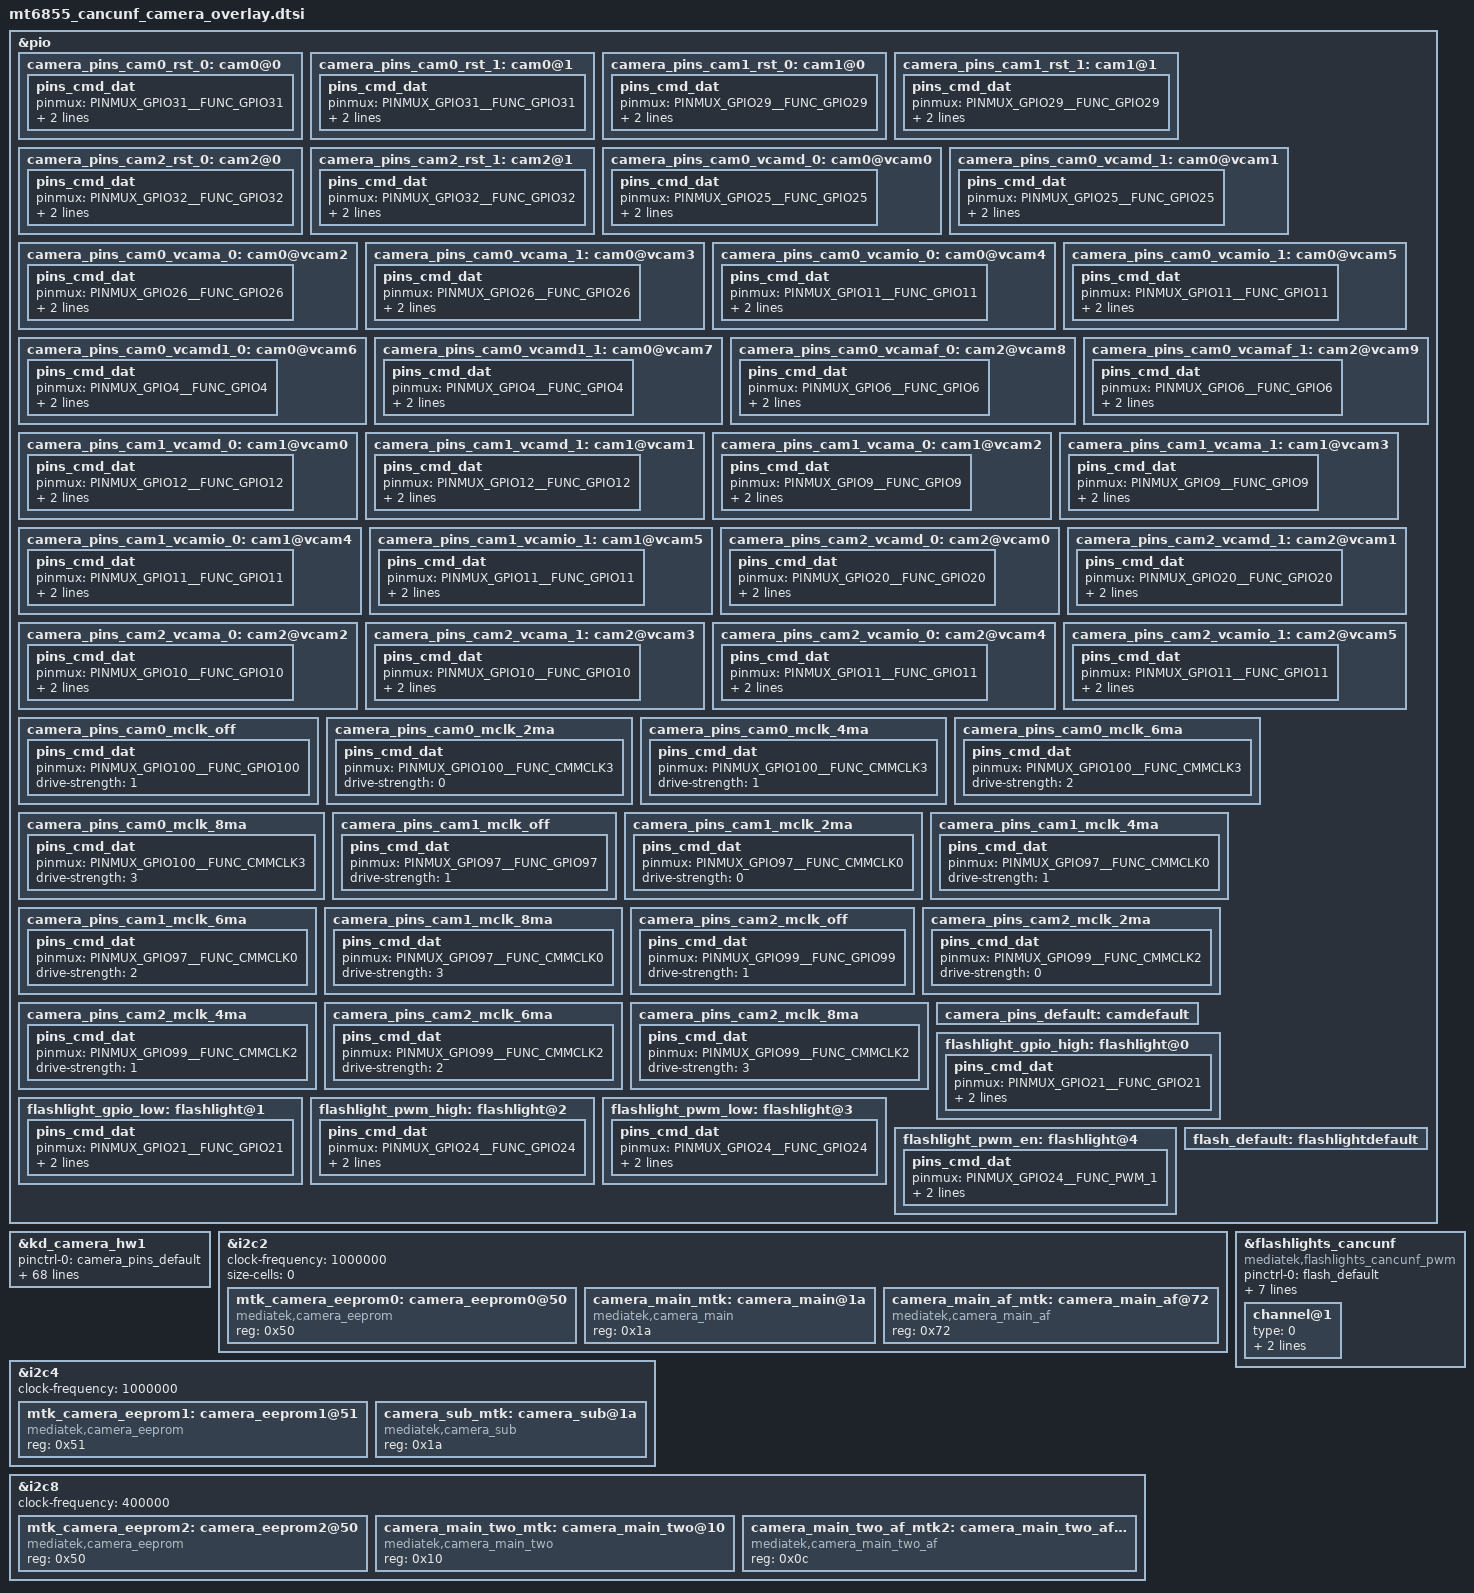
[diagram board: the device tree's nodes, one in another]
// SPDX-License-Identifier: GPL-2.0
/* Copyright (c) 2020 MediaTek Inc. */
/* CAMERA GPIO standardization */
&pio {
	camera_pins_cam0_rst_0: cam0@0 {
		pins_cmd_dat {
			pinmux = <PINMUX_GPIO31__FUNC_GPIO31>;
			slew-rate = <1>;
			output-low;
		};
	};
	camera_pins_cam0_rst_1: cam0@1 {
		pins_cmd_dat {
			pinmux = <PINMUX_GPIO31__FUNC_GPIO31>;
			slew-rate = <1>;
			output-high;
		};
	};
	camera_pins_cam1_rst_0: cam1@0 {
		pins_cmd_dat {
			pinmux = <PINMUX_GPIO29__FUNC_GPIO29>;
			slew-rate = <1>;
			output-low;
		};
	};
	camera_pins_cam1_rst_1: cam1@1 {
		pins_cmd_dat {
			pinmux = <PINMUX_GPIO29__FUNC_GPIO29>;
			slew-rate = <1>;
			output-high;
		};
	};
	camera_pins_cam2_rst_0: cam2@0 {
		pins_cmd_dat {
			pinmux = <PINMUX_GPIO32__FUNC_GPIO32>;
			slew-rate = <1>;
			output-low;
		};
	};
	camera_pins_cam2_rst_1: cam2@1 {
		pins_cmd_dat {
			pinmux = <PINMUX_GPIO32__FUNC_GPIO32>;
			slew-rate = <1>;
			output-high;
		};
	};
	camera_pins_cam0_vcamd_0: cam0@vcam0 {
		pins_cmd_dat {
			pinmux = <PINMUX_GPIO25__FUNC_GPIO25>;
			slew-rate = <1>;
			output-low;
		};
	};
	camera_pins_cam0_vcamd_1: cam0@vcam1 {
		pins_cmd_dat {
			pinmux = <PINMUX_GPIO25__FUNC_GPIO25>;
			slew-rate = <1>;
			output-high;
		};
	};
	camera_pins_cam0_vcama_0: cam0@vcam2 {
		pins_cmd_dat {
			pinmux = <PINMUX_GPIO26__FUNC_GPIO26>;
			slew-rate = <1>;
			output-low;
		};
	};
	camera_pins_cam0_vcama_1: cam0@vcam3 {
		pins_cmd_dat {
			pinmux = <PINMUX_GPIO26__FUNC_GPIO26>;
			slew-rate = <1>;
			output-high;
		};
	};
	camera_pins_cam0_vcamio_0: cam0@vcam4 {
		pins_cmd_dat {
			pinmux = <PINMUX_GPIO11__FUNC_GPIO11>;
			slew-rate = <1>;
			output-low;
		};
	};
	camera_pins_cam0_vcamio_1: cam0@vcam5 {
		pins_cmd_dat {
			pinmux = <PINMUX_GPIO11__FUNC_GPIO11>;
			slew-rate = <1>;
			output-high;
		};
	};
	camera_pins_cam0_vcamd1_0: cam0@vcam6 {
		pins_cmd_dat {
		pinmux = <PINMUX_GPIO4__FUNC_GPIO4>;
			slew-rate = <1>;
			output-low;
		};
	};
	camera_pins_cam0_vcamd1_1: cam0@vcam7 {
		pins_cmd_dat {
			pinmux = <PINMUX_GPIO4__FUNC_GPIO4>;
			slew-rate = <1>;
			output-high;
		};
	};
	camera_pins_cam0_vcamaf_0: cam2@vcam8 {
		pins_cmd_dat {
			pinmux = <PINMUX_GPIO6__FUNC_GPIO6>;
			slew-rate = <1>;
			output-low;
		};
	};
	camera_pins_cam0_vcamaf_1: cam2@vcam9 {
		pins_cmd_dat {
			pinmux = <PINMUX_GPIO6__FUNC_GPIO6>;
			slew-rate = <1>;
			output-high;
		};
	};
	camera_pins_cam1_vcamd_0: cam1@vcam0 {
		pins_cmd_dat {
			pinmux = <PINMUX_GPIO12__FUNC_GPIO12>;
			slew-rate = <1>;
			output-low;
		};
	};
	camera_pins_cam1_vcamd_1: cam1@vcam1 {
		pins_cmd_dat {
			pinmux = <PINMUX_GPIO12__FUNC_GPIO12>;
			slew-rate = <1>;
			output-high;
		};
	};
	camera_pins_cam1_vcama_0: cam1@vcam2 {
		pins_cmd_dat {
			pinmux = <PINMUX_GPIO9__FUNC_GPIO9>;
			slew-rate = <1>;
			output-low;
		};
	};
	camera_pins_cam1_vcama_1: cam1@vcam3 {
		pins_cmd_dat {
			pinmux = <PINMUX_GPIO9__FUNC_GPIO9>;
			slew-rate = <1>;
			output-high;
		};
	};
	camera_pins_cam1_vcamio_0: cam1@vcam4 {
		pins_cmd_dat {
			pinmux = <PINMUX_GPIO11__FUNC_GPIO11>;
			slew-rate = <1>;
			output-low;
		};
	};
	camera_pins_cam1_vcamio_1: cam1@vcam5 {
		pins_cmd_dat {
			pinmux = <PINMUX_GPIO11__FUNC_GPIO11>;
			slew-rate = <1>;
			output-high;
		};
	};
	camera_pins_cam2_vcamd_0: cam2@vcam0 {
		pins_cmd_dat {
			pinmux = <PINMUX_GPIO20__FUNC_GPIO20>;
			slew-rate = <1>;
			output-low;
		};
	};
	camera_pins_cam2_vcamd_1: cam2@vcam1 {
		pins_cmd_dat {
			pinmux = <PINMUX_GPIO20__FUNC_GPIO20>;
			slew-rate = <1>;
			output-high;
		};
	};
	camera_pins_cam2_vcama_0: cam2@vcam2 {
		pins_cmd_dat {
			pinmux = <PINMUX_GPIO10__FUNC_GPIO10>;
			slew-rate = <1>;
			output-low;
		};
	};
	camera_pins_cam2_vcama_1: cam2@vcam3 {
		pins_cmd_dat {
			pinmux = <PINMUX_GPIO10__FUNC_GPIO10>;
			slew-rate = <1>;
			output-high;
		};
	};
	camera_pins_cam2_vcamio_0: cam2@vcam4 {
		pins_cmd_dat {
			pinmux = <PINMUX_GPIO11__FUNC_GPIO11>;
			slew-rate = <1>;
			output-low;
		};
	};
	camera_pins_cam2_vcamio_1: cam2@vcam5 {
		pins_cmd_dat {
			pinmux = <PINMUX_GPIO11__FUNC_GPIO11>;
			slew-rate = <1>;
			output-high;
		};
	};
	camera_pins_cam0_mclk_off: camera_pins_cam0_mclk_off {
		pins_cmd_dat {
			pinmux = <PINMUX_GPIO100__FUNC_GPIO100>;
			drive-strength = <1>;
		};
	};
	camera_pins_cam0_mclk_2ma: camera_pins_cam0_mclk_2ma {
		pins_cmd_dat {
			pinmux = <PINMUX_GPIO100__FUNC_CMMCLK3>;
			drive-strength = <0>;
		};
	};
	camera_pins_cam0_mclk_4ma: camera_pins_cam0_mclk_4ma {
		pins_cmd_dat {
			pinmux = <PINMUX_GPIO100__FUNC_CMMCLK3>;
			drive-strength = <1>;
		};
	};
	camera_pins_cam0_mclk_6ma: camera_pins_cam0_mclk_6ma {
		pins_cmd_dat {
			pinmux = <PINMUX_GPIO100__FUNC_CMMCLK3>;
			drive-strength = <2>;
		};
	};
	camera_pins_cam0_mclk_8ma: camera_pins_cam0_mclk_8ma {
		pins_cmd_dat {
			pinmux = <PINMUX_GPIO100__FUNC_CMMCLK3>;
			drive-strength = <3>;
		};
	};
	camera_pins_cam1_mclk_off: camera_pins_cam1_mclk_off {
		pins_cmd_dat {
			pinmux = <PINMUX_GPIO97__FUNC_GPIO97>;
			drive-strength = <1>;
		};
	};
	camera_pins_cam1_mclk_2ma: camera_pins_cam1_mclk_2ma {
		pins_cmd_dat {
			pinmux = <PINMUX_GPIO97__FUNC_CMMCLK0>;
			drive-strength = <0>;
		};
	};
	camera_pins_cam1_mclk_4ma: camera_pins_cam1_mclk_4ma {
		pins_cmd_dat {
			pinmux = <PINMUX_GPIO97__FUNC_CMMCLK0>;
			drive-strength = <1>;
		};
	};
	camera_pins_cam1_mclk_6ma: camera_pins_cam1_mclk_6ma {
		pins_cmd_dat {
			pinmux = <PINMUX_GPIO97__FUNC_CMMCLK0>;
			drive-strength = <2>;
		};
	};
	camera_pins_cam1_mclk_8ma: camera_pins_cam1_mclk_8ma {
		pins_cmd_dat {
			pinmux = <PINMUX_GPIO97__FUNC_CMMCLK0>;
			drive-strength = <3>;
		};
	};
	camera_pins_cam2_mclk_off: camera_pins_cam2_mclk_off {
		pins_cmd_dat {
			pinmux = <PINMUX_GPIO99__FUNC_GPIO99>;
			drive-strength = <1>;
		};
	};
	camera_pins_cam2_mclk_2ma: camera_pins_cam2_mclk_2ma {
		pins_cmd_dat {
			pinmux = <PINMUX_GPIO99__FUNC_CMMCLK2>;
			drive-strength = <0>;
		};
	};
	camera_pins_cam2_mclk_4ma: camera_pins_cam2_mclk_4ma {
		pins_cmd_dat {
			pinmux = <PINMUX_GPIO99__FUNC_CMMCLK2>;
			drive-strength = <1>;
		};
	};
	camera_pins_cam2_mclk_6ma: camera_pins_cam2_mclk_6ma {
		pins_cmd_dat {
			pinmux = <PINMUX_GPIO99__FUNC_CMMCLK2>;
			drive-strength = <2>;
		};
	};
	camera_pins_cam2_mclk_8ma: camera_pins_cam2_mclk_8ma {
		pins_cmd_dat {
			pinmux = <PINMUX_GPIO99__FUNC_CMMCLK2>;
			drive-strength = <3>;
		};
	};
	camera_pins_default: camdefault {
	};
	flashlight_gpio_high: flashlight@0 {
		pins_cmd_dat {
			pinmux = <PINMUX_GPIO21__FUNC_GPIO21>;
			slew-rate = <1>;
			output-high;
		};
	};
	flashlight_gpio_low: flashlight@1 {
		pins_cmd_dat {
			pinmux = <PINMUX_GPIO21__FUNC_GPIO21>;
			slew-rate = <1>;
			output-low;
		};
	};
	flashlight_pwm_high: flashlight@2 {
		pins_cmd_dat {
			pinmux = <PINMUX_GPIO24__FUNC_GPIO24>;
			slew-rate = <1>;
			output-high;
		};
	};
	flashlight_pwm_low: flashlight@3 {
		pins_cmd_dat {
			pinmux = <PINMUX_GPIO24__FUNC_GPIO24>;
			slew-rate = <1>;
			output-low;
		};
	};
	flashlight_pwm_en: flashlight@4 {
		pins_cmd_dat {
			pinmux = <PINMUX_GPIO24__FUNC_PWM_1>;
			slew-rate = <1>;
			output-high;
		};
	};
	flash_default: flashlightdefault {
	};
};
&kd_camera_hw1 {
	pinctrl-names = "default",
			"cam0_rst0", "cam0_rst1",
			"cam1_rst0", "cam1_rst1",
			"cam2_rst0", "cam2_rst1",
			"cam0_ldo_vcamd_0", "cam0_ldo_vcamd_1",
			"cam0_ldo_vcama_0", "cam0_ldo_vcama_1",
			"cam0_ldo_vcamio_0", "cam0_ldo_vcamio_1",
			"cam1_ldo_vcamd_0", "cam1_ldo_vcamd_1",
			"cam1_ldo_vcama_0", "cam1_ldo_vcama_1",
			"cam1_ldo_vcamio_0", "cam1_ldo_vcamio_1",
			"cam2_ldo_vcamd_0", "cam2_ldo_vcamd_1",
			"cam2_ldo_vcama_0", "cam2_ldo_vcama_1",
			"cam2_ldo_vcamio_0", "cam2_ldo_vcamio_1",
			"cam0_ldo_vcamaf_0", "cam0_ldo_vcamaf_1",
			"cam0_mclk_off",
			"cam0_mclk_2mA", "cam0_mclk_4mA",
			"cam0_mclk_6mA", "cam0_mclk_8mA",
			"cam1_mclk_off",
			"cam1_mclk_2mA", "cam1_mclk_4mA",
			"cam1_mclk_6mA", "cam1_mclk_8mA",
			"cam2_mclk_off",
			"cam2_mclk_2mA", "cam2_mclk_4mA",
			"cam2_mclk_6mA", "cam2_mclk_8mA",
			"cam0_ldo_vcamd1_0", "cam0_ldo_vcamd1_1";
	pinctrl-0 = <&camera_pins_default>;
	pinctrl-1 = <&camera_pins_cam0_rst_0>;
	pinctrl-2 = <&camera_pins_cam0_rst_1>;
	pinctrl-3 = <&camera_pins_cam1_rst_0>;
	pinctrl-4 = <&camera_pins_cam1_rst_1>;
	pinctrl-5 = <&camera_pins_cam2_rst_0>;
	pinctrl-6 = <&camera_pins_cam2_rst_1>;
	pinctrl-7 = <&camera_pins_cam0_vcamd_0>;
	pinctrl-8 = <&camera_pins_cam0_vcamd_1>;
	pinctrl-9 = <&camera_pins_cam0_vcama_0>;
	pinctrl-10 = <&camera_pins_cam0_vcama_1>;
	pinctrl-11 = <&camera_pins_cam0_vcamio_0>;
	pinctrl-12 = <&camera_pins_cam0_vcamio_1>;
	pinctrl-13 = <&camera_pins_cam1_vcamd_0>;
	pinctrl-14 = <&camera_pins_cam1_vcamd_1>;
	pinctrl-15 = <&camera_pins_cam1_vcama_0>;
	pinctrl-16 = <&camera_pins_cam1_vcama_1>;
	pinctrl-17 = <&camera_pins_cam1_vcamio_0>;
	pinctrl-18 = <&camera_pins_cam1_vcamio_1>;
	pinctrl-19 = <&camera_pins_cam2_vcamd_0>;
	pinctrl-20 = <&camera_pins_cam2_vcamd_1>;
	pinctrl-21 = <&camera_pins_cam2_vcama_0>;
	pinctrl-22 = <&camera_pins_cam2_vcama_1>;
	pinctrl-23 = <&camera_pins_cam2_vcamio_0>;
	pinctrl-24 = <&camera_pins_cam2_vcamio_1>;
	pinctrl-25 = <&camera_pins_cam0_vcamaf_0>;
	pinctrl-26 = <&camera_pins_cam0_vcamaf_1>;
	pinctrl-27 = <&camera_pins_cam0_mclk_off>;
	pinctrl-28 = <&camera_pins_cam0_mclk_2ma>;
	pinctrl-29 = <&camera_pins_cam0_mclk_4ma>;
	pinctrl-30 = <&camera_pins_cam0_mclk_6ma>;
	pinctrl-31 = <&camera_pins_cam0_mclk_8ma>;
	pinctrl-32 = <&camera_pins_cam1_mclk_off>;
	pinctrl-33 = <&camera_pins_cam1_mclk_2ma>;
	pinctrl-34 = <&camera_pins_cam1_mclk_4ma>;
	pinctrl-35 = <&camera_pins_cam1_mclk_6ma>;
	pinctrl-36 = <&camera_pins_cam1_mclk_8ma>;
	pinctrl-37 = <&camera_pins_cam2_mclk_off>;
	pinctrl-38 = <&camera_pins_cam2_mclk_2ma>;
	pinctrl-39 = <&camera_pins_cam2_mclk_4ma>;
	pinctrl-40 = <&camera_pins_cam2_mclk_6ma>;
	pinctrl-41 = <&camera_pins_cam2_mclk_8ma>;
	pinctrl-42 = <&camera_pins_cam0_vcamd1_0>;
	pinctrl-43 = <&camera_pins_cam0_vcamd1_1>;

	cam2_vcamaf-supply = <&mt6369_vtp>;


	cam0_pin_mclk = "mclk";
	cam0_pin_rst = "gpio";
	cam0_pin_vcama = "gpio";
	cam0_pin_vcamd = "gpio";
	cam0_pin_vcamio = "gpio";
	cam0_pin_vcamd1 = "gpio";
	cam0_pin_vcamaf = "gpio";
	cam1_pin_mclk = "mclk";
	cam1_pin_rst = "gpio";
	cam1_pin_vcama = "gpio";
	cam1_pin_vcamd = "gpio";
	cam1_pin_vcamio = "gpio";
	cam2_pin_mclk = "mclk";
	cam2_pin_rst = "gpio";
	cam2_pin_vcama = "gpio";
	cam2_pin_vcamd = "gpio";
	cam2_pin_vcamio = "gpio";
	cam2_pin_vcamaf = "regulator";

	cam0_enable_sensor = "mot_cancunf_ov50d_mipi_raw mot_cancunf_s5kjns_mipi_raw mot_cancunf_s5kjns_vcm_yova";
	cam1_enable_sensor = "mot_cancunf_hi1634q_mipi_raw mot_cancunf_s5k3p9sp04_mipi_raw";
	cam2_enable_sensor = "mot_cancunf_s5k4h7_mipi_raw mot_cancunf_sc202_mipi_raw";

	status = "okay";
};
/* CAMERA GPIO end */


/* CAMERA EEPROM */
&i2c2 {
	status = "okay";
	clock-frequency = <1000000>;
	#address-cells = <1>;
	size-cells = <0>;
	mtk_camera_eeprom0:camera_eeprom0@50 {
		compatible = "mediatek,camera_eeprom";
		reg = <0x50>;
		status = "okay";
	};
	camera_main_mtk:camera_main@1a {
		compatible = "mediatek,camera_main";
		#thermal-sensor-cells = <0>;
		reg = <0x1a>;
		status = "okay";
	};
};
&i2c4 {
	status = "okay";
	clock-frequency = <1000000>;
	#address-cells = <1>;
	#size-cells = <0>;
	mtk_camera_eeprom1:camera_eeprom1@51 {
		compatible = "mediatek,camera_eeprom";
		reg = <0x51>;
		status = "okay";
	};
	camera_sub_mtk:camera_sub@1a {
		compatible = "mediatek,camera_sub";
		#thermal-sensor-cells = <0>;
		reg = <0x1a>;
		status = "okay";
	};
};
&i2c8 {
	status = "okay";
	clock-frequency = <400000>;
	#address-cells = <1>;
	#size-cells = <0>;
	mtk_camera_eeprom2:camera_eeprom2@50 {
		compatible = "mediatek,camera_eeprom";
		reg = <0x50>;
		status = "okay";
	};
	camera_main_two_mtk:camera_main_two@10 {
		compatible = "mediatek,camera_main_two";
		#thermal-sensor-cells = <0>;
		reg = <0x10>;
		status = "okay";
	};
};
/* CAMERA EEPROM end */
/* CAMERA Flashlight */
&flashlights_cancunf {
	compatible = "mediatek,flashlights_cancunf_pwm";
	pinctrl-names = "default",
		"flashlight_gpio_high",
		"flashlight_gpio_low",
		"flashlight_pwm_high",
		"flashlight_pwm_low",
		"flashlight_pwm_en";

	pinctrl-0 = <&flash_default>;
	pinctrl-1 = <&flashlight_gpio_high>;
	pinctrl-2 = <&flashlight_gpio_low>;
	pinctrl-3 = <&flashlight_pwm_high>;
	pinctrl-4 = <&flashlight_pwm_low>;
	pinctrl-5 = <&flashlight_pwm_en>;
        srcclk = <&pericfg_ao_clk>;

	decouple = <1>;
	channel@1 {
                status = "okay";
		type = <0>;
		ct = <0>;
		part = <0>;
	};
};
/* CAMERA Flashlight end */
/* CAMERA AF */
&i2c2 {
	camera_main_af_mtk:camera_main_af@72 {
		compatible = "mediatek,camera_main_af";
		reg = <0x72>;
		status = "okay";
	};

};
&i2c8 {
	camera_main_two_af_mtk2:camera_main_two_af@0c {
		compatible = "mediatek,camera_main_two_af";
		reg = <0x0c>;
		status = "okay";
	};
};
/* CAMERA AF end */
